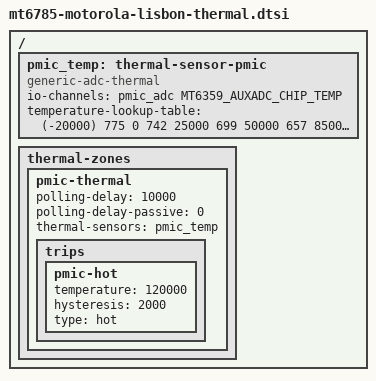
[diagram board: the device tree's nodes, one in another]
// SPDX-License-Identifier: (GPL-2.0 OR MIT)
/*
 * Motorola Moto G60s (lisbon): chip temperature of the MT6359 PMIC as a thermal zone (monitoring
 * only).
 *
 * Channel CHIP_TEMP of the MT6359 AUXADC (mV). Conversion as in the vendor kernel, T = intercept +
 * 1000000 * V / -(1681 - slope), with the efuse values o_vts 1599, degc_cali 47, slope 0 (per-unit
 * calibration, not read at runtime): T[mC] = 441108 - 1000000 * V[mV] / 1681. The table is derived
 * from that (linear, rounded). Below 531 mV the zone reports 125 C (end of table), so there is only
 * a "hot" trip without action (no shutdown). Trip 120 C is the vendor default for the PMIC zone.
 */

#include <dt-bindings/iio/adc/mediatek,mt6359-auxadc.h>

/ {
	pmic_temp: thermal-sensor-pmic {
		compatible = "generic-adc-thermal";
		#thermal-sensor-cells = <0>;
		io-channels = <&pmic_adc MT6359_AUXADC_CHIP_TEMP>;
		io-channel-names = "sensor-channel";
		temperature-lookup-table = <
			(-20000) 775  0 742  25000 699  50000 657
			85000 599  100000 573  125000 531>;
	};

	thermal-zones {
		pmic-thermal {
			polling-delay = <10000>;
			polling-delay-passive = <0>;
			thermal-sensors = <&pmic_temp>;

			trips {
				pmic-hot {
					temperature = <120000>;
					hysteresis = <2000>;
					type = "hot";
				};
			};
		};
	};
};
